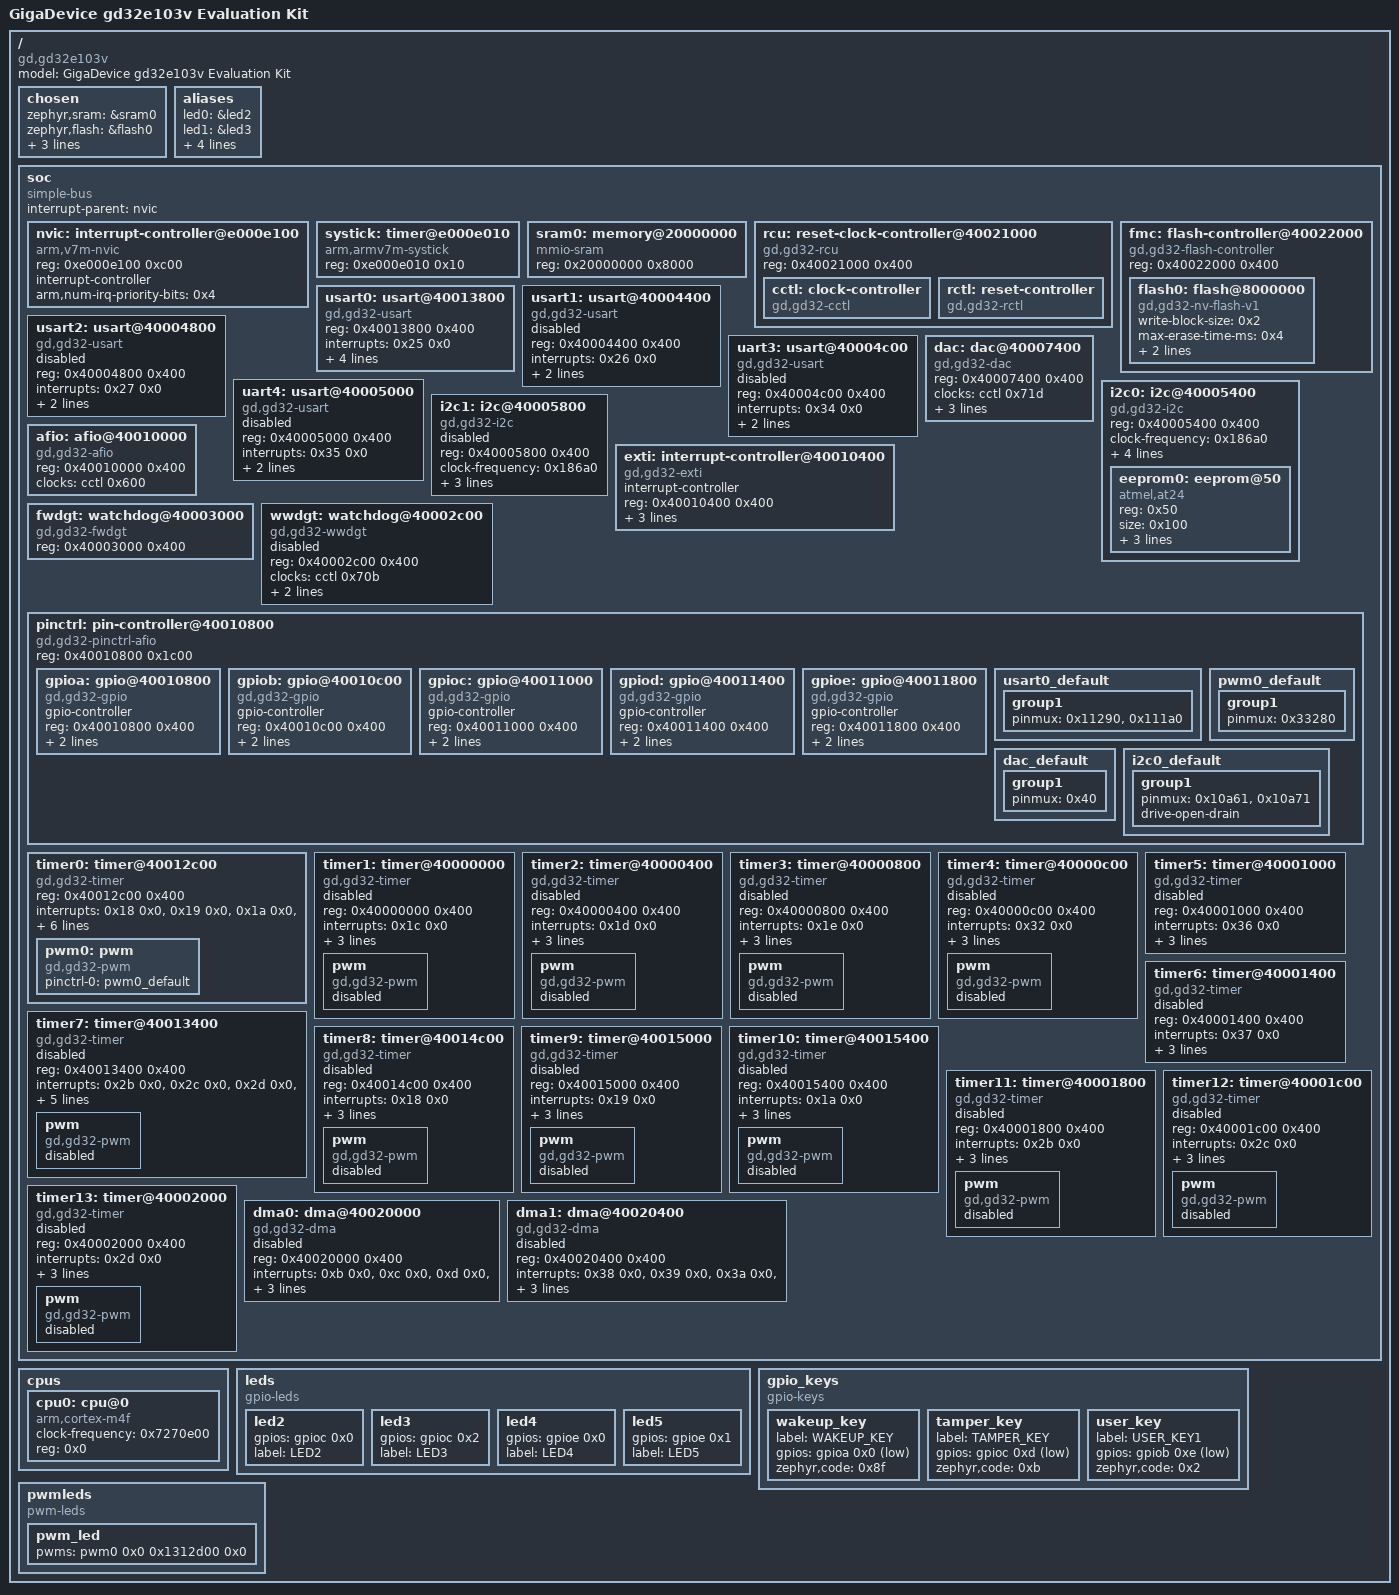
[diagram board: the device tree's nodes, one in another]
/dts-v1/;

/* node '/' defined in zephyr/dts/common/skeleton.dtsi:9 */
/ {
	#address-cells = < 0x1 >;                      /* in zephyr/dts/common/skeleton.dtsi:10 */
	#size-cells = < 0x1 >;                         /* in zephyr/dts/common/skeleton.dtsi:11 */
	model = "GigaDevice gd32e103v Evaluation Kit"; /* in zephyr/boards/gd/gd32e103v_eval/gd32e103v_eval.dts:13 */
	compatible = "gd,gd32e103v";                   /* in zephyr/boards/gd/gd32e103v_eval/gd32e103v_eval.dts:14 */

	/* node '/chosen' defined in zephyr/dts/common/skeleton.dtsi:13 */
	chosen {
		zephyr,sram = &sram0;           /* in zephyr/boards/gd/gd32e103v_eval/gd32e103v_eval.dts:17 */
		zephyr,flash = &flash0;         /* in zephyr/boards/gd/gd32e103v_eval/gd32e103v_eval.dts:18 */
		zephyr,console = &usart0;       /* in zephyr/boards/gd/gd32e103v_eval/gd32e103v_eval.dts:19 */
		zephyr,shell-uart = &usart0;    /* in zephyr/boards/gd/gd32e103v_eval/gd32e103v_eval.dts:20 */
		zephyr,flash-controller = &fmc; /* in zephyr/boards/gd/gd32e103v_eval/gd32e103v_eval.dts:21 */
	};

	/* node '/aliases' defined in zephyr/dts/common/skeleton.dtsi:15 */
	aliases {
		led0 = &led2;        /* in zephyr/boards/gd/gd32e103v_eval/gd32e103v_eval.dts:80 */
		led1 = &led3;        /* in zephyr/boards/gd/gd32e103v_eval/gd32e103v_eval.dts:81 */
		sw0 = &user_key;     /* in zephyr/boards/gd/gd32e103v_eval/gd32e103v_eval.dts:82 */
		pwm-led0 = &pwm_led; /* in zephyr/boards/gd/gd32e103v_eval/gd32e103v_eval.dts:83 */
		eeprom-0 = &eeprom0; /* in zephyr/boards/gd/gd32e103v_eval/gd32e103v_eval.dts:84 */
		watchdog0 = &fwdgt;  /* in zephyr/boards/gd/gd32e103v_eval/gd32e103v_eval.dts:85 */
	};

	/* node '/soc' defined in zephyr/dts/arm/armv7-m.dtsi:6 */
	soc {
		#address-cells = < 0x1 >;     /* in zephyr/dts/arm/armv7-m.dtsi:7 */
		#size-cells = < 0x1 >;        /* in zephyr/dts/arm/armv7-m.dtsi:8 */
		compatible = "simple-bus";    /* in zephyr/dts/arm/armv7-m.dtsi:9 */
		interrupt-parent = < &nvic >; /* in zephyr/dts/arm/armv7-m.dtsi:10 */
		ranges;                       /* in zephyr/dts/arm/armv7-m.dtsi:11 */

		/* node '/soc/interrupt-controller@e000e100' defined in zephyr/dts/arm/armv7-m.dtsi:13 */
		nvic: interrupt-controller@e000e100 {
			#address-cells = < 0x1 >;            /* in zephyr/dts/arm/armv7-m.dtsi:14 */
			compatible = "arm,v7m-nvic";         /* in zephyr/dts/arm/armv7-m.dtsi:15 */
			reg = < 0xe000e100 0xc00 >;          /* in zephyr/dts/arm/armv7-m.dtsi:16 */
			interrupt-controller;                /* in zephyr/dts/arm/armv7-m.dtsi:17 */
			#interrupt-cells = < 0x2 >;          /* in zephyr/dts/arm/armv7-m.dtsi:18 */
			arm,num-irq-priority-bits = < 0x4 >; /* in zephyr/dts/arm/gd/gd32e10x/gd32e10x.dtsi:493 */
			phandle = < 0x1 >;                   /* in zephyr/dts/arm/armv7-m.dtsi:10 */
		};

		/* node '/soc/timer@e000e010' defined in zephyr/dts/arm/armv7-m.dtsi:21 */
		systick: timer@e000e010 {
			compatible = "arm,armv7m-systick"; /* in zephyr/dts/arm/armv7-m.dtsi:22 */
			reg = < 0xe000e010 0x10 >;         /* in zephyr/dts/arm/armv7-m.dtsi:23 */
		};

		/* node '/soc/memory@20000000' defined in zephyr/dts/arm/gd/gd32e10x/gd32e10x.dtsi:30 */
		sram0: memory@20000000 {
			compatible = "mmio-sram";    /* in zephyr/dts/arm/gd/gd32e10x/gd32e10x.dtsi:31 */
			reg = < 0x20000000 0x8000 >; /* in zephyr/dts/arm/gd/gd32e10x/gd32e103vbt6.dtsi:15 */
		};

		/* node '/soc/reset-clock-controller@40021000' defined in zephyr/dts/arm/gd/gd32e10x/gd32e10x.dtsi:34 */
		rcu: reset-clock-controller@40021000 {
			compatible = "gd,gd32-rcu"; /* in zephyr/dts/arm/gd/gd32e10x/gd32e10x.dtsi:35 */
			reg = < 0x40021000 0x400 >; /* in zephyr/dts/arm/gd/gd32e10x/gd32e10x.dtsi:36 */
			status = "okay";            /* in zephyr/dts/arm/gd/gd32e10x/gd32e10x.dtsi:37 */

			/* node '/soc/reset-clock-controller@40021000/clock-controller' defined in zephyr/dts/arm/gd/gd32e10x/gd32e10x.dtsi:39 */
			cctl: clock-controller {
				compatible = "gd,gd32-cctl"; /* in zephyr/dts/arm/gd/gd32e10x/gd32e10x.dtsi:40 */
				#clock-cells = < 0x1 >;      /* in zephyr/dts/arm/gd/gd32e10x/gd32e10x.dtsi:41 */
				status = "okay";             /* in zephyr/dts/arm/gd/gd32e10x/gd32e10x.dtsi:42 */
				phandle = < 0x2 >;           /* in zephyr/dts/arm/gd/gd32e10x/gd32e10x.dtsi:70 */
			};

			/* node '/soc/reset-clock-controller@40021000/reset-controller' defined in zephyr/dts/arm/gd/gd32e10x/gd32e10x.dtsi:45 */
			rctl: reset-controller {
				compatible = "gd,gd32-rctl"; /* in zephyr/dts/arm/gd/gd32e10x/gd32e10x.dtsi:46 */
				#reset-cells = < 0x1 >;      /* in zephyr/dts/arm/gd/gd32e10x/gd32e10x.dtsi:47 */
				status = "okay";             /* in zephyr/dts/arm/gd/gd32e10x/gd32e10x.dtsi:48 */
				phandle = < 0x3 >;           /* in zephyr/dts/arm/gd/gd32e10x/gd32e10x.dtsi:71 */
			};
		};

		/* node '/soc/flash-controller@40022000' defined in zephyr/dts/arm/gd/gd32e10x/gd32e10x.dtsi:52 */
		fmc: flash-controller@40022000 {
			compatible = "gd,gd32-flash-controller"; /* in zephyr/dts/arm/gd/gd32e10x/gd32e10x.dtsi:53 */
			reg = < 0x40022000 0x400 >;              /* in zephyr/dts/arm/gd/gd32e10x/gd32e10x.dtsi:54 */
			#address-cells = < 0x1 >;                /* in zephyr/dts/arm/gd/gd32e10x/gd32e10x.dtsi:55 */
			#size-cells = < 0x1 >;                   /* in zephyr/dts/arm/gd/gd32e10x/gd32e10x.dtsi:56 */

			/* node '/soc/flash-controller@40022000/flash@8000000' defined in zephyr/dts/arm/gd/gd32e10x/gd32e10x.dtsi:58 */
			flash0: flash@8000000 {
				compatible = "gd,gd32-nv-flash-v1",
				             "soc-nv-flash";        /* in zephyr/dts/arm/gd/gd32e10x/gd32e10x.dtsi:59 */
				write-block-size = < 0x2 >;         /* in zephyr/dts/arm/gd/gd32e10x/gd32e10x.dtsi:60 */
				max-erase-time-ms = < 0x4 >;        /* in zephyr/dts/arm/gd/gd32e10x/gd32e10x.dtsi:61 */
				page-size = < 0x400 >;              /* in zephyr/dts/arm/gd/gd32e10x/gd32e10x.dtsi:62 */
				reg = < 0x8000000 0x20000 >;        /* in zephyr/dts/arm/gd/gd32e10x/gd32e103vbt6.dtsi:11 */
			};
		};

		/* node '/soc/usart@40013800' defined in zephyr/dts/arm/gd/gd32e10x/gd32e10x.dtsi:66 */
		usart0: usart@40013800 {
			compatible = "gd,gd32-usart";    /* in zephyr/dts/arm/gd/gd32e10x/gd32e10x.dtsi:67 */
			reg = < 0x40013800 0x400 >;      /* in zephyr/dts/arm/gd/gd32e10x/gd32e10x.dtsi:68 */
			interrupts = < 0x25 0x0 >;       /* in zephyr/dts/arm/gd/gd32e10x/gd32e10x.dtsi:69 */
			clocks = < &cctl 0x60e >;        /* in zephyr/dts/arm/gd/gd32e10x/gd32e10x.dtsi:70 */
			resets = < &rctl 0x30e >;        /* in zephyr/dts/arm/gd/gd32e10x/gd32e10x.dtsi:71 */
			status = "okay";                 /* in zephyr/boards/gd/gd32e103v_eval/gd32e103v_eval.dts:110 */
			current-speed = < 0x1c200 >;     /* in zephyr/boards/gd/gd32e103v_eval/gd32e103v_eval.dts:111 */
			pinctrl-0 = < &usart0_default >; /* in zephyr/boards/gd/gd32e103v_eval/gd32e103v_eval.dts:112 */
			pinctrl-names = "default";       /* in zephyr/boards/gd/gd32e103v_eval/gd32e103v_eval.dts:113 */
		};

		/* node '/soc/usart@40004400' defined in zephyr/dts/arm/gd/gd32e10x/gd32e10x.dtsi:75 */
		usart1: usart@40004400 {
			compatible = "gd,gd32-usart"; /* in zephyr/dts/arm/gd/gd32e10x/gd32e10x.dtsi:76 */
			reg = < 0x40004400 0x400 >;   /* in zephyr/dts/arm/gd/gd32e10x/gd32e10x.dtsi:77 */
			interrupts = < 0x26 0x0 >;    /* in zephyr/dts/arm/gd/gd32e10x/gd32e10x.dtsi:78 */
			clocks = < &cctl 0x711 >;     /* in zephyr/dts/arm/gd/gd32e10x/gd32e10x.dtsi:79 */
			resets = < &rctl 0x411 >;     /* in zephyr/dts/arm/gd/gd32e10x/gd32e10x.dtsi:80 */
			status = "disabled";          /* in zephyr/dts/arm/gd/gd32e10x/gd32e10x.dtsi:81 */
		};

		/* node '/soc/usart@40004800' defined in zephyr/dts/arm/gd/gd32e10x/gd32e10x.dtsi:84 */
		usart2: usart@40004800 {
			compatible = "gd,gd32-usart"; /* in zephyr/dts/arm/gd/gd32e10x/gd32e10x.dtsi:85 */
			reg = < 0x40004800 0x400 >;   /* in zephyr/dts/arm/gd/gd32e10x/gd32e10x.dtsi:86 */
			interrupts = < 0x27 0x0 >;    /* in zephyr/dts/arm/gd/gd32e10x/gd32e10x.dtsi:87 */
			clocks = < &cctl 0x712 >;     /* in zephyr/dts/arm/gd/gd32e10x/gd32e10x.dtsi:88 */
			resets = < &rctl 0x412 >;     /* in zephyr/dts/arm/gd/gd32e10x/gd32e10x.dtsi:89 */
			status = "disabled";          /* in zephyr/dts/arm/gd/gd32e10x/gd32e10x.dtsi:90 */
		};

		/* node '/soc/usart@40004c00' defined in zephyr/dts/arm/gd/gd32e10x/gd32e10x.dtsi:93 */
		uart3: usart@40004c00 {
			compatible = "gd,gd32-usart"; /* in zephyr/dts/arm/gd/gd32e10x/gd32e10x.dtsi:94 */
			reg = < 0x40004c00 0x400 >;   /* in zephyr/dts/arm/gd/gd32e10x/gd32e10x.dtsi:95 */
			interrupts = < 0x34 0x0 >;    /* in zephyr/dts/arm/gd/gd32e10x/gd32e10x.dtsi:96 */
			clocks = < &cctl 0x713 >;     /* in zephyr/dts/arm/gd/gd32e10x/gd32e10x.dtsi:97 */
			resets = < &rctl 0x413 >;     /* in zephyr/dts/arm/gd/gd32e10x/gd32e10x.dtsi:98 */
			status = "disabled";          /* in zephyr/dts/arm/gd/gd32e10x/gd32e10x.dtsi:99 */
		};

		/* node '/soc/usart@40005000' defined in zephyr/dts/arm/gd/gd32e10x/gd32e10x.dtsi:102 */
		uart4: usart@40005000 {
			compatible = "gd,gd32-usart"; /* in zephyr/dts/arm/gd/gd32e10x/gd32e10x.dtsi:103 */
			reg = < 0x40005000 0x400 >;   /* in zephyr/dts/arm/gd/gd32e10x/gd32e10x.dtsi:104 */
			interrupts = < 0x35 0x0 >;    /* in zephyr/dts/arm/gd/gd32e10x/gd32e10x.dtsi:105 */
			clocks = < &cctl 0x714 >;     /* in zephyr/dts/arm/gd/gd32e10x/gd32e10x.dtsi:106 */
			resets = < &rctl 0x414 >;     /* in zephyr/dts/arm/gd/gd32e10x/gd32e10x.dtsi:107 */
			status = "disabled";          /* in zephyr/dts/arm/gd/gd32e10x/gd32e10x.dtsi:108 */
		};

		/* node '/soc/dac@40007400' defined in zephyr/dts/arm/gd/gd32e10x/gd32e10x.dtsi:111 */
		dac: dac@40007400 {
			compatible = "gd,gd32-dac";   /* in zephyr/dts/arm/gd/gd32e10x/gd32e10x.dtsi:112 */
			reg = < 0x40007400 0x400 >;   /* in zephyr/dts/arm/gd/gd32e10x/gd32e10x.dtsi:113 */
			clocks = < &cctl 0x71d >;     /* in zephyr/dts/arm/gd/gd32e10x/gd32e10x.dtsi:114 */
			resets = < &rctl 0x41d >;     /* in zephyr/dts/arm/gd/gd32e10x/gd32e10x.dtsi:115 */
			num-channels = < 0x2 >;       /* in zephyr/dts/arm/gd/gd32e10x/gd32e10x.dtsi:116 */
			#io-channel-cells = < 0x1 >;  /* in zephyr/dts/arm/gd/gd32e10x/gd32e10x.dtsi:118 */
			status = "okay";              /* in zephyr/boards/gd/gd32e103v_eval/gd32e103v_eval.dts:144 */
			pinctrl-0 = < &dac_default >; /* in zephyr/boards/gd/gd32e103v_eval/gd32e103v_eval.dts:145 */
			pinctrl-names = "default";    /* in zephyr/boards/gd/gd32e103v_eval/gd32e103v_eval.dts:146 */
		};

		/* node '/soc/i2c@40005400' defined in zephyr/dts/arm/gd/gd32e10x/gd32e10x.dtsi:121 */
		i2c0: i2c@40005400 {
			compatible = "gd,gd32-i2c";    /* in zephyr/dts/arm/gd/gd32e10x/gd32e10x.dtsi:122 */
			reg = < 0x40005400 0x400 >;    /* in zephyr/dts/arm/gd/gd32e10x/gd32e10x.dtsi:123 */
			#address-cells = < 0x1 >;      /* in zephyr/dts/arm/gd/gd32e10x/gd32e10x.dtsi:124 */
			#size-cells = < 0x0 >;         /* in zephyr/dts/arm/gd/gd32e10x/gd32e10x.dtsi:125 */
			clock-frequency = < 0x186a0 >; /* in zephyr/dts/arm/gd/gd32e10x/gd32e10x.dtsi:126 */
			interrupts = < 0x1f 0x0 >,
			             < 0x20 0x0 >;     /* in zephyr/dts/arm/gd/gd32e10x/gd32e10x.dtsi:127 */
			interrupt-names = "event",
			                  "error";     /* in zephyr/dts/arm/gd/gd32e10x/gd32e10x.dtsi:128 */
			clocks = < &cctl 0x715 >;      /* in zephyr/dts/arm/gd/gd32e10x/gd32e10x.dtsi:129 */
			resets = < &rctl 0x415 >;      /* in zephyr/dts/arm/gd/gd32e10x/gd32e10x.dtsi:130 */
			status = "okay";               /* in zephyr/boards/gd/gd32e103v_eval/gd32e103v_eval.dts:128 */
			pinctrl-0 = < &i2c0_default >; /* in zephyr/boards/gd/gd32e103v_eval/gd32e103v_eval.dts:129 */
			pinctrl-names = "default";     /* in zephyr/boards/gd/gd32e103v_eval/gd32e103v_eval.dts:130 */

			/* node '/soc/i2c@40005400/eeprom@50' defined in zephyr/boards/gd/gd32e103v_eval/gd32e103v_eval.dts:132 */
			eeprom0: eeprom@50 {
				compatible = "atmel,at24"; /* in zephyr/boards/gd/gd32e103v_eval/gd32e103v_eval.dts:133 */
				reg = < 0x50 >;            /* in zephyr/boards/gd/gd32e103v_eval/gd32e103v_eval.dts:134 */
				status = "okay";           /* in zephyr/boards/gd/gd32e103v_eval/gd32e103v_eval.dts:135 */
				size = < 0x100 >;          /* in zephyr/boards/gd/gd32e103v_eval/gd32e103v_eval.dts:136 */
				pagesize = < 0x8 >;        /* in zephyr/boards/gd/gd32e103v_eval/gd32e103v_eval.dts:137 */
				address-width = < 0x8 >;   /* in zephyr/boards/gd/gd32e103v_eval/gd32e103v_eval.dts:138 */
				timeout = < 0x5 >;         /* in zephyr/boards/gd/gd32e103v_eval/gd32e103v_eval.dts:139 */
			};
		};

		/* node '/soc/i2c@40005800' defined in zephyr/dts/arm/gd/gd32e10x/gd32e10x.dtsi:134 */
		i2c1: i2c@40005800 {
			compatible = "gd,gd32-i2c";    /* in zephyr/dts/arm/gd/gd32e10x/gd32e10x.dtsi:135 */
			reg = < 0x40005800 0x400 >;    /* in zephyr/dts/arm/gd/gd32e10x/gd32e10x.dtsi:136 */
			#address-cells = < 0x1 >;      /* in zephyr/dts/arm/gd/gd32e10x/gd32e10x.dtsi:137 */
			#size-cells = < 0x0 >;         /* in zephyr/dts/arm/gd/gd32e10x/gd32e10x.dtsi:138 */
			clock-frequency = < 0x186a0 >; /* in zephyr/dts/arm/gd/gd32e10x/gd32e10x.dtsi:139 */
			interrupts = < 0x21 0x0 >,
			             < 0x22 0x0 >;     /* in zephyr/dts/arm/gd/gd32e10x/gd32e10x.dtsi:140 */
			interrupt-names = "event",
			                  "error";     /* in zephyr/dts/arm/gd/gd32e10x/gd32e10x.dtsi:141 */
			clocks = < &cctl 0x716 >;      /* in zephyr/dts/arm/gd/gd32e10x/gd32e10x.dtsi:142 */
			resets = < &rctl 0x416 >;      /* in zephyr/dts/arm/gd/gd32e10x/gd32e10x.dtsi:143 */
			status = "disabled";           /* in zephyr/dts/arm/gd/gd32e10x/gd32e10x.dtsi:144 */
		};

		/* node '/soc/afio@40010000' defined in zephyr/dts/arm/gd/gd32e10x/gd32e10x.dtsi:147 */
		afio: afio@40010000 {
			compatible = "gd,gd32-afio"; /* in zephyr/dts/arm/gd/gd32e10x/gd32e10x.dtsi:148 */
			reg = < 0x40010000 0x400 >;  /* in zephyr/dts/arm/gd/gd32e10x/gd32e10x.dtsi:149 */
			clocks = < &cctl 0x600 >;    /* in zephyr/dts/arm/gd/gd32e10x/gd32e10x.dtsi:150 */
			status = "okay";             /* in zephyr/dts/arm/gd/gd32e10x/gd32e10x.dtsi:151 */
		};

		/* node '/soc/interrupt-controller@40010400' defined in zephyr/dts/arm/gd/gd32e10x/gd32e10x.dtsi:154 */
		exti: interrupt-controller@40010400 {
			compatible = "gd,gd32-exti";   /* in zephyr/dts/arm/gd/gd32e10x/gd32e10x.dtsi:155 */
			interrupt-controller;          /* in zephyr/dts/arm/gd/gd32e10x/gd32e10x.dtsi:156 */
			#interrupt-cells = < 0x1 >;    /* in zephyr/dts/arm/gd/gd32e10x/gd32e10x.dtsi:157 */
			reg = < 0x40010400 0x400 >;    /* in zephyr/dts/arm/gd/gd32e10x/gd32e10x.dtsi:158 */
			num-lines = < 0x13 >;          /* in zephyr/dts/arm/gd/gd32e10x/gd32e10x.dtsi:159 */
			interrupts = < 0x6 0x0 >,
			             < 0x7 0x0 >,
			             < 0x8 0x0 >,
			             < 0x9 0x0 >,
			             < 0xa 0x0 >,
			             < 0x17 0x0 >,
			             < 0x28 0x0 >;     /* in zephyr/dts/arm/gd/gd32e10x/gd32e10x.dtsi:160 */
			interrupt-names = "line0",
			                  "line1",
			                  "line2",
			                  "line3",
			                  "line4",
			                  "line5-9",
			                  "line10-15"; /* in zephyr/dts/arm/gd/gd32e10x/gd32e10x.dtsi:162 */
			status = "okay";               /* in zephyr/dts/arm/gd/gd32e10x/gd32e10x.dtsi:164 */
		};

		/* node '/soc/watchdog@40003000' defined in zephyr/dts/arm/gd/gd32e10x/gd32e10x.dtsi:167 */
		fwdgt: watchdog@40003000 {
			compatible = "gd,gd32-fwdgt"; /* in zephyr/dts/arm/gd/gd32e10x/gd32e10x.dtsi:168 */
			reg = < 0x40003000 0x400 >;   /* in zephyr/dts/arm/gd/gd32e10x/gd32e10x.dtsi:169 */
			status = "okay";              /* in zephyr/boards/gd/gd32e103v_eval/gd32e103v_eval.dts:150 */
		};

		/* node '/soc/watchdog@40002c00' defined in zephyr/dts/arm/gd/gd32e10x/gd32e10x.dtsi:173 */
		wwdgt: watchdog@40002c00 {
			compatible = "gd,gd32-wwdgt"; /* in zephyr/dts/arm/gd/gd32e10x/gd32e10x.dtsi:174 */
			reg = < 0x40002c00 0x400 >;   /* in zephyr/dts/arm/gd/gd32e10x/gd32e10x.dtsi:175 */
			clocks = < &cctl 0x70b >;     /* in zephyr/dts/arm/gd/gd32e10x/gd32e10x.dtsi:176 */
			resets = < &rctl 0x40b >;     /* in zephyr/dts/arm/gd/gd32e10x/gd32e10x.dtsi:177 */
			interrupts = < 0x0 0x0 >;     /* in zephyr/dts/arm/gd/gd32e10x/gd32e10x.dtsi:178 */
			status = "disabled";          /* in zephyr/dts/arm/gd/gd32e10x/gd32e10x.dtsi:179 */
		};

		/* node '/soc/pin-controller@40010800' defined in zephyr/dts/arm/gd/gd32e10x/gd32e10x.dtsi:182 */
		pinctrl: pin-controller@40010800 {
			compatible = "gd,gd32-pinctrl-afio"; /* in zephyr/dts/arm/gd/gd32e10x/gd32e10x.dtsi:183 */
			reg = < 0x40010800 0x1c00 >;         /* in zephyr/dts/arm/gd/gd32e10x/gd32e10x.dtsi:184 */
			#address-cells = < 0x1 >;            /* in zephyr/dts/arm/gd/gd32e10x/gd32e10x.dtsi:185 */
			#size-cells = < 0x1 >;               /* in zephyr/dts/arm/gd/gd32e10x/gd32e10x.dtsi:186 */
			status = "okay";                     /* in zephyr/dts/arm/gd/gd32e10x/gd32e10x.dtsi:187 */

			/* node '/soc/pin-controller@40010800/gpio@40010800' defined in zephyr/dts/arm/gd/gd32e10x/gd32e10x.dtsi:189 */
			gpioa: gpio@40010800 {
				compatible = "gd,gd32-gpio"; /* in zephyr/dts/arm/gd/gd32e10x/gd32e10x.dtsi:190 */
				gpio-controller;             /* in zephyr/dts/arm/gd/gd32e10x/gd32e10x.dtsi:191 */
				#gpio-cells = < 0x2 >;       /* in zephyr/dts/arm/gd/gd32e10x/gd32e10x.dtsi:192 */
				reg = < 0x40010800 0x400 >;  /* in zephyr/dts/arm/gd/gd32e10x/gd32e10x.dtsi:193 */
				clocks = < &cctl 0x602 >;    /* in zephyr/dts/arm/gd/gd32e10x/gd32e10x.dtsi:194 */
				resets = < &rctl 0x302 >;    /* in zephyr/dts/arm/gd/gd32e10x/gd32e10x.dtsi:195 */
				status = "okay";             /* in zephyr/boards/gd/gd32e103v_eval/gd32e103v_eval.dts:90 */
				phandle = < 0xa >;           /* in zephyr/boards/gd/gd32e103v_eval/gd32e103v_eval.dts:53 */
			};

			/* node '/soc/pin-controller@40010800/gpio@40010c00' defined in zephyr/dts/arm/gd/gd32e10x/gd32e10x.dtsi:199 */
			gpiob: gpio@40010c00 {
				compatible = "gd,gd32-gpio"; /* in zephyr/dts/arm/gd/gd32e10x/gd32e10x.dtsi:200 */
				gpio-controller;             /* in zephyr/dts/arm/gd/gd32e10x/gd32e10x.dtsi:201 */
				#gpio-cells = < 0x2 >;       /* in zephyr/dts/arm/gd/gd32e10x/gd32e10x.dtsi:202 */
				reg = < 0x40010c00 0x400 >;  /* in zephyr/dts/arm/gd/gd32e10x/gd32e10x.dtsi:203 */
				clocks = < &cctl 0x603 >;    /* in zephyr/dts/arm/gd/gd32e10x/gd32e10x.dtsi:204 */
				resets = < &rctl 0x303 >;    /* in zephyr/dts/arm/gd/gd32e10x/gd32e10x.dtsi:205 */
				status = "okay";             /* in zephyr/boards/gd/gd32e103v_eval/gd32e103v_eval.dts:94 */
				phandle = < 0xb >;           /* in zephyr/boards/gd/gd32e103v_eval/gd32e103v_eval.dts:65 */
			};

			/* node '/soc/pin-controller@40010800/gpio@40011000' defined in zephyr/dts/arm/gd/gd32e10x/gd32e10x.dtsi:209 */
			gpioc: gpio@40011000 {
				compatible = "gd,gd32-gpio"; /* in zephyr/dts/arm/gd/gd32e10x/gd32e10x.dtsi:210 */
				gpio-controller;             /* in zephyr/dts/arm/gd/gd32e10x/gd32e10x.dtsi:211 */
				#gpio-cells = < 0x2 >;       /* in zephyr/dts/arm/gd/gd32e10x/gd32e10x.dtsi:212 */
				reg = < 0x40011000 0x400 >;  /* in zephyr/dts/arm/gd/gd32e10x/gd32e10x.dtsi:213 */
				clocks = < &cctl 0x604 >;    /* in zephyr/dts/arm/gd/gd32e10x/gd32e10x.dtsi:214 */
				resets = < &rctl 0x304 >;    /* in zephyr/dts/arm/gd/gd32e10x/gd32e10x.dtsi:215 */
				status = "okay";             /* in zephyr/boards/gd/gd32e103v_eval/gd32e103v_eval.dts:98 */
				phandle = < 0x8 >;           /* in zephyr/boards/gd/gd32e103v_eval/gd32e103v_eval.dts:28 */
			};

			/* node '/soc/pin-controller@40010800/gpio@40011400' defined in zephyr/dts/arm/gd/gd32e10x/gd32e10x.dtsi:219 */
			gpiod: gpio@40011400 {
				compatible = "gd,gd32-gpio"; /* in zephyr/dts/arm/gd/gd32e10x/gd32e10x.dtsi:220 */
				gpio-controller;             /* in zephyr/dts/arm/gd/gd32e10x/gd32e10x.dtsi:221 */
				#gpio-cells = < 0x2 >;       /* in zephyr/dts/arm/gd/gd32e10x/gd32e10x.dtsi:222 */
				reg = < 0x40011400 0x400 >;  /* in zephyr/dts/arm/gd/gd32e10x/gd32e10x.dtsi:223 */
				clocks = < &cctl 0x605 >;    /* in zephyr/dts/arm/gd/gd32e10x/gd32e10x.dtsi:224 */
				resets = < &rctl 0x305 >;    /* in zephyr/dts/arm/gd/gd32e10x/gd32e10x.dtsi:225 */
				status = "okay";             /* in zephyr/boards/gd/gd32e103v_eval/gd32e103v_eval.dts:102 */
			};

			/* node '/soc/pin-controller@40010800/gpio@40011800' defined in zephyr/dts/arm/gd/gd32e10x/gd32e10x.dtsi:229 */
			gpioe: gpio@40011800 {
				compatible = "gd,gd32-gpio"; /* in zephyr/dts/arm/gd/gd32e10x/gd32e10x.dtsi:230 */
				gpio-controller;             /* in zephyr/dts/arm/gd/gd32e10x/gd32e10x.dtsi:231 */
				#gpio-cells = < 0x2 >;       /* in zephyr/dts/arm/gd/gd32e10x/gd32e10x.dtsi:232 */
				reg = < 0x40011800 0x400 >;  /* in zephyr/dts/arm/gd/gd32e10x/gd32e10x.dtsi:233 */
				clocks = < &cctl 0x606 >;    /* in zephyr/dts/arm/gd/gd32e10x/gd32e10x.dtsi:234 */
				resets = < &rctl 0x306 >;    /* in zephyr/dts/arm/gd/gd32e10x/gd32e10x.dtsi:235 */
				status = "okay";             /* in zephyr/boards/gd/gd32e103v_eval/gd32e103v_eval.dts:106 */
				phandle = < 0x9 >;           /* in zephyr/boards/gd/gd32e103v_eval/gd32e103v_eval.dts:38 */
			};

			/* node '/soc/pin-controller@40010800/usart0_default' defined in zephyr/boards/gd/gd32e103v_eval/gd32e103v_eval-pinctrl.dtsi:9 */
			usart0_default: usart0_default {
				phandle = < 0x4 >; /* in zephyr/boards/gd/gd32e103v_eval/gd32e103v_eval.dts:112 */

				/* node '/soc/pin-controller@40010800/usart0_default/group1' defined in zephyr/boards/gd/gd32e103v_eval/gd32e103v_eval-pinctrl.dtsi:10 */
				group1 {
					pinmux = < 0x11290 >,
					         < 0x111a0 >; /* in zephyr/boards/gd/gd32e103v_eval/gd32e103v_eval-pinctrl.dtsi:11 */
				};
			};

			/* node '/soc/pin-controller@40010800/pwm0_default' defined in zephyr/boards/gd/gd32e103v_eval/gd32e103v_eval-pinctrl.dtsi:15 */
			pwm0_default: pwm0_default {
				phandle = < 0x7 >; /* in zephyr/boards/gd/gd32e103v_eval/gd32e103v_eval.dts:122 */

				/* node '/soc/pin-controller@40010800/pwm0_default/group1' defined in zephyr/boards/gd/gd32e103v_eval/gd32e103v_eval-pinctrl.dtsi:16 */
				group1 {
					pinmux = < 0x33280 >; /* in zephyr/boards/gd/gd32e103v_eval/gd32e103v_eval-pinctrl.dtsi:17 */
				};
			};

			/* node '/soc/pin-controller@40010800/dac_default' defined in zephyr/boards/gd/gd32e103v_eval/gd32e103v_eval-pinctrl.dtsi:21 */
			dac_default: dac_default {
				phandle = < 0x5 >; /* in zephyr/boards/gd/gd32e103v_eval/gd32e103v_eval.dts:145 */

				/* node '/soc/pin-controller@40010800/dac_default/group1' defined in zephyr/boards/gd/gd32e103v_eval/gd32e103v_eval-pinctrl.dtsi:22 */
				group1 {
					pinmux = < 0x40 >; /* in zephyr/boards/gd/gd32e103v_eval/gd32e103v_eval-pinctrl.dtsi:23 */
				};
			};

			/* node '/soc/pin-controller@40010800/i2c0_default' defined in zephyr/boards/gd/gd32e103v_eval/gd32e103v_eval-pinctrl.dtsi:27 */
			i2c0_default: i2c0_default {
				phandle = < 0x6 >; /* in zephyr/boards/gd/gd32e103v_eval/gd32e103v_eval.dts:129 */

				/* node '/soc/pin-controller@40010800/i2c0_default/group1' defined in zephyr/boards/gd/gd32e103v_eval/gd32e103v_eval-pinctrl.dtsi:28 */
				group1 {
					pinmux = < 0x10a61 >,
					         < 0x10a71 >; /* in zephyr/boards/gd/gd32e103v_eval/gd32e103v_eval-pinctrl.dtsi:29 */
					drive-open-drain;     /* in zephyr/boards/gd/gd32e103v_eval/gd32e103v_eval-pinctrl.dtsi:30 */
				};
			};
		};

		/* node '/soc/timer@40012c00' defined in zephyr/dts/arm/gd/gd32e10x/gd32e10x.dtsi:240 */
		timer0: timer@40012c00 {
			compatible = "gd,gd32-timer"; /* in zephyr/dts/arm/gd/gd32e10x/gd32e10x.dtsi:241 */
			reg = < 0x40012c00 0x400 >;   /* in zephyr/dts/arm/gd/gd32e10x/gd32e10x.dtsi:242 */
			interrupts = < 0x18 0x0 >,
			             < 0x19 0x0 >,
			             < 0x1a 0x0 >,
			             < 0x1b 0x0 >;    /* in zephyr/dts/arm/gd/gd32e10x/gd32e10x.dtsi:243 */
			interrupt-names = "brk",
			                  "up",
			                  "trgcom",
			                  "cc";       /* in zephyr/dts/arm/gd/gd32e10x/gd32e10x.dtsi:244 */
			clocks = < &cctl 0x60b >;     /* in zephyr/dts/arm/gd/gd32e10x/gd32e10x.dtsi:245 */
			resets = < &rctl 0x30b >;     /* in zephyr/dts/arm/gd/gd32e10x/gd32e10x.dtsi:246 */
			is-advanced;                  /* in zephyr/dts/arm/gd/gd32e10x/gd32e10x.dtsi:247 */
			channels = < 0x4 >;           /* in zephyr/dts/arm/gd/gd32e10x/gd32e10x.dtsi:248 */
			status = "okay";              /* in zephyr/boards/gd/gd32e103v_eval/gd32e103v_eval.dts:117 */
			prescaler = < 0x80 >;         /* in zephyr/boards/gd/gd32e103v_eval/gd32e103v_eval.dts:118 */

			/* node '/soc/timer@40012c00/pwm' defined in zephyr/dts/arm/gd/gd32e10x/gd32e10x.dtsi:251 */
			pwm0: pwm {
				compatible = "gd,gd32-pwm";    /* in zephyr/dts/arm/gd/gd32e10x/gd32e10x.dtsi:252 */
				#pwm-cells = < 0x3 >;          /* in zephyr/dts/arm/gd/gd32e10x/gd32e10x.dtsi:254 */
				status = "okay";               /* in zephyr/boards/gd/gd32e103v_eval/gd32e103v_eval.dts:121 */
				pinctrl-0 = < &pwm0_default >; /* in zephyr/boards/gd/gd32e103v_eval/gd32e103v_eval.dts:122 */
				pinctrl-names = "default";     /* in zephyr/boards/gd/gd32e103v_eval/gd32e103v_eval.dts:123 */
				phandle = < 0xc >;             /* in zephyr/boards/gd/gd32e103v_eval/gd32e103v_eval.dts:75 */
			};
		};

		/* node '/soc/timer@40000000' defined in zephyr/dts/arm/gd/gd32e10x/gd32e10x.dtsi:258 */
		timer1: timer@40000000 {
			compatible = "gd,gd32-timer"; /* in zephyr/dts/arm/gd/gd32e10x/gd32e10x.dtsi:259 */
			reg = < 0x40000000 0x400 >;   /* in zephyr/dts/arm/gd/gd32e10x/gd32e10x.dtsi:260 */
			interrupts = < 0x1c 0x0 >;    /* in zephyr/dts/arm/gd/gd32e10x/gd32e10x.dtsi:261 */
			interrupt-names = "global";   /* in zephyr/dts/arm/gd/gd32e10x/gd32e10x.dtsi:262 */
			clocks = < &cctl 0x700 >;     /* in zephyr/dts/arm/gd/gd32e10x/gd32e10x.dtsi:263 */
			resets = < &rctl 0x400 >;     /* in zephyr/dts/arm/gd/gd32e10x/gd32e10x.dtsi:264 */
			channels = < 0x4 >;           /* in zephyr/dts/arm/gd/gd32e10x/gd32e10x.dtsi:265 */
			status = "disabled";          /* in zephyr/dts/arm/gd/gd32e10x/gd32e10x.dtsi:266 */

			/* node '/soc/timer@40000000/pwm' defined in zephyr/dts/arm/gd/gd32e10x/gd32e10x.dtsi:268 */
			pwm {
				compatible = "gd,gd32-pwm"; /* in zephyr/dts/arm/gd/gd32e10x/gd32e10x.dtsi:269 */
				status = "disabled";        /* in zephyr/dts/arm/gd/gd32e10x/gd32e10x.dtsi:270 */
				#pwm-cells = < 0x3 >;       /* in zephyr/dts/arm/gd/gd32e10x/gd32e10x.dtsi:271 */
			};
		};

		/* node '/soc/timer@40000400' defined in zephyr/dts/arm/gd/gd32e10x/gd32e10x.dtsi:275 */
		timer2: timer@40000400 {
			compatible = "gd,gd32-timer"; /* in zephyr/dts/arm/gd/gd32e10x/gd32e10x.dtsi:276 */
			reg = < 0x40000400 0x400 >;   /* in zephyr/dts/arm/gd/gd32e10x/gd32e10x.dtsi:277 */
			interrupts = < 0x1d 0x0 >;    /* in zephyr/dts/arm/gd/gd32e10x/gd32e10x.dtsi:278 */
			interrupt-names = "global";   /* in zephyr/dts/arm/gd/gd32e10x/gd32e10x.dtsi:279 */
			clocks = < &cctl 0x701 >;     /* in zephyr/dts/arm/gd/gd32e10x/gd32e10x.dtsi:280 */
			resets = < &rctl 0x401 >;     /* in zephyr/dts/arm/gd/gd32e10x/gd32e10x.dtsi:281 */
			channels = < 0x4 >;           /* in zephyr/dts/arm/gd/gd32e10x/gd32e10x.dtsi:282 */
			status = "disabled";          /* in zephyr/dts/arm/gd/gd32e10x/gd32e10x.dtsi:283 */

			/* node '/soc/timer@40000400/pwm' defined in zephyr/dts/arm/gd/gd32e10x/gd32e10x.dtsi:285 */
			pwm {
				compatible = "gd,gd32-pwm"; /* in zephyr/dts/arm/gd/gd32e10x/gd32e10x.dtsi:286 */
				status = "disabled";        /* in zephyr/dts/arm/gd/gd32e10x/gd32e10x.dtsi:287 */
				#pwm-cells = < 0x3 >;       /* in zephyr/dts/arm/gd/gd32e10x/gd32e10x.dtsi:288 */
			};
		};

		/* node '/soc/timer@40000800' defined in zephyr/dts/arm/gd/gd32e10x/gd32e10x.dtsi:292 */
		timer3: timer@40000800 {
			compatible = "gd,gd32-timer"; /* in zephyr/dts/arm/gd/gd32e10x/gd32e10x.dtsi:293 */
			reg = < 0x40000800 0x400 >;   /* in zephyr/dts/arm/gd/gd32e10x/gd32e10x.dtsi:294 */
			interrupts = < 0x1e 0x0 >;    /* in zephyr/dts/arm/gd/gd32e10x/gd32e10x.dtsi:295 */
			interrupt-names = "global";   /* in zephyr/dts/arm/gd/gd32e10x/gd32e10x.dtsi:296 */
			clocks = < &cctl 0x702 >;     /* in zephyr/dts/arm/gd/gd32e10x/gd32e10x.dtsi:297 */
			resets = < &rctl 0x402 >;     /* in zephyr/dts/arm/gd/gd32e10x/gd32e10x.dtsi:298 */
			channels = < 0x4 >;           /* in zephyr/dts/arm/gd/gd32e10x/gd32e10x.dtsi:299 */
			status = "disabled";          /* in zephyr/dts/arm/gd/gd32e10x/gd32e10x.dtsi:300 */

			/* node '/soc/timer@40000800/pwm' defined in zephyr/dts/arm/gd/gd32e10x/gd32e10x.dtsi:302 */
			pwm {
				compatible = "gd,gd32-pwm"; /* in zephyr/dts/arm/gd/gd32e10x/gd32e10x.dtsi:303 */
				status = "disabled";        /* in zephyr/dts/arm/gd/gd32e10x/gd32e10x.dtsi:304 */
				#pwm-cells = < 0x3 >;       /* in zephyr/dts/arm/gd/gd32e10x/gd32e10x.dtsi:305 */
			};
		};

		/* node '/soc/timer@40000c00' defined in zephyr/dts/arm/gd/gd32e10x/gd32e10x.dtsi:309 */
		timer4: timer@40000c00 {
			compatible = "gd,gd32-timer"; /* in zephyr/dts/arm/gd/gd32e10x/gd32e10x.dtsi:310 */
			reg = < 0x40000c00 0x400 >;   /* in zephyr/dts/arm/gd/gd32e10x/gd32e10x.dtsi:311 */
			interrupts = < 0x32 0x0 >;    /* in zephyr/dts/arm/gd/gd32e10x/gd32e10x.dtsi:312 */
			interrupt-names = "global";   /* in zephyr/dts/arm/gd/gd32e10x/gd32e10x.dtsi:313 */
			clocks = < &cctl 0x703 >;     /* in zephyr/dts/arm/gd/gd32e10x/gd32e10x.dtsi:314 */
			resets = < &rctl 0x403 >;     /* in zephyr/dts/arm/gd/gd32e10x/gd32e10x.dtsi:315 */
			channels = < 0x4 >;           /* in zephyr/dts/arm/gd/gd32e10x/gd32e10x.dtsi:316 */
			status = "disabled";          /* in zephyr/dts/arm/gd/gd32e10x/gd32e10x.dtsi:317 */

			/* node '/soc/timer@40000c00/pwm' defined in zephyr/dts/arm/gd/gd32e10x/gd32e10x.dtsi:319 */
			pwm {
				compatible = "gd,gd32-pwm"; /* in zephyr/dts/arm/gd/gd32e10x/gd32e10x.dtsi:320 */
				status = "disabled";        /* in zephyr/dts/arm/gd/gd32e10x/gd32e10x.dtsi:321 */
				#pwm-cells = < 0x3 >;       /* in zephyr/dts/arm/gd/gd32e10x/gd32e10x.dtsi:322 */
			};
		};

		/* node '/soc/timer@40001000' defined in zephyr/dts/arm/gd/gd32e10x/gd32e10x.dtsi:326 */
		timer5: timer@40001000 {
			compatible = "gd,gd32-timer"; /* in zephyr/dts/arm/gd/gd32e10x/gd32e10x.dtsi:327 */
			reg = < 0x40001000 0x400 >;   /* in zephyr/dts/arm/gd/gd32e10x/gd32e10x.dtsi:328 */
			interrupts = < 0x36 0x0 >;    /* in zephyr/dts/arm/gd/gd32e10x/gd32e10x.dtsi:329 */
			interrupt-names = "global";   /* in zephyr/dts/arm/gd/gd32e10x/gd32e10x.dtsi:330 */
			clocks = < &cctl 0x704 >;     /* in zephyr/dts/arm/gd/gd32e10x/gd32e10x.dtsi:331 */
			resets = < &rctl 0x404 >;     /* in zephyr/dts/arm/gd/gd32e10x/gd32e10x.dtsi:332 */
			channels = < 0x0 >;           /* in zephyr/dts/arm/gd/gd32e10x/gd32e10x.dtsi:333 */
			status = "disabled";          /* in zephyr/dts/arm/gd/gd32e10x/gd32e10x.dtsi:334 */
		};

		/* node '/soc/timer@40001400' defined in zephyr/dts/arm/gd/gd32e10x/gd32e10x.dtsi:337 */
		timer6: timer@40001400 {
			compatible = "gd,gd32-timer"; /* in zephyr/dts/arm/gd/gd32e10x/gd32e10x.dtsi:338 */
			reg = < 0x40001400 0x400 >;   /* in zephyr/dts/arm/gd/gd32e10x/gd32e10x.dtsi:339 */
			interrupts = < 0x37 0x0 >;    /* in zephyr/dts/arm/gd/gd32e10x/gd32e10x.dtsi:340 */
			interrupt-names = "global";   /* in zephyr/dts/arm/gd/gd32e10x/gd32e10x.dtsi:341 */
			clocks = < &cctl 0x705 >;     /* in zephyr/dts/arm/gd/gd32e10x/gd32e10x.dtsi:342 */
			resets = < &rctl 0x405 >;     /* in zephyr/dts/arm/gd/gd32e10x/gd32e10x.dtsi:343 */
			channels = < 0x0 >;           /* in zephyr/dts/arm/gd/gd32e10x/gd32e10x.dtsi:344 */
			status = "disabled";          /* in zephyr/dts/arm/gd/gd32e10x/gd32e10x.dtsi:345 */
		};

		/* node '/soc/timer@40013400' defined in zephyr/dts/arm/gd/gd32e10x/gd32e10x.dtsi:348 */
		timer7: timer@40013400 {
			compatible = "gd,gd32-timer"; /* in zephyr/dts/arm/gd/gd32e10x/gd32e10x.dtsi:349 */
			reg = < 0x40013400 0x400 >;   /* in zephyr/dts/arm/gd/gd32e10x/gd32e10x.dtsi:350 */
			interrupts = < 0x2b 0x0 >,
			             < 0x2c 0x0 >,
			             < 0x2d 0x0 >,
			             < 0x2e 0x0 >;    /* in zephyr/dts/arm/gd/gd32e10x/gd32e10x.dtsi:351 */
			interrupt-names = "brk",
			                  "up",
			                  "trgcom",
			                  "cc";       /* in zephyr/dts/arm/gd/gd32e10x/gd32e10x.dtsi:352 */
			clocks = < &cctl 0x60d >;     /* in zephyr/dts/arm/gd/gd32e10x/gd32e10x.dtsi:353 */
			resets = < &rctl 0x30d >;     /* in zephyr/dts/arm/gd/gd32e10x/gd32e10x.dtsi:354 */
			is-advanced;                  /* in zephyr/dts/arm/gd/gd32e10x/gd32e10x.dtsi:355 */
			channels = < 0x4 >;           /* in zephyr/dts/arm/gd/gd32e10x/gd32e10x.dtsi:356 */
			status = "disabled";          /* in zephyr/dts/arm/gd/gd32e10x/gd32e10x.dtsi:357 */

			/* node '/soc/timer@40013400/pwm' defined in zephyr/dts/arm/gd/gd32e10x/gd32e10x.dtsi:359 */
			pwm {
				compatible = "gd,gd32-pwm"; /* in zephyr/dts/arm/gd/gd32e10x/gd32e10x.dtsi:360 */
				status = "disabled";        /* in zephyr/dts/arm/gd/gd32e10x/gd32e10x.dtsi:361 */
				#pwm-cells = < 0x3 >;       /* in zephyr/dts/arm/gd/gd32e10x/gd32e10x.dtsi:362 */
			};
		};

		/* node '/soc/timer@40014c00' defined in zephyr/dts/arm/gd/gd32e10x/gd32e10x.dtsi:366 */
		timer8: timer@40014c00 {
			compatible = "gd,gd32-timer"; /* in zephyr/dts/arm/gd/gd32e10x/gd32e10x.dtsi:367 */
			reg = < 0x40014c00 0x400 >;   /* in zephyr/dts/arm/gd/gd32e10x/gd32e10x.dtsi:368 */
			interrupts = < 0x18 0x0 >;    /* in zephyr/dts/arm/gd/gd32e10x/gd32e10x.dtsi:369 */
			interrupt-names = "global";   /* in zephyr/dts/arm/gd/gd32e10x/gd32e10x.dtsi:370 */
			clocks = < &cctl 0x613 >;     /* in zephyr/dts/arm/gd/gd32e10x/gd32e10x.dtsi:371 */
			resets = < &rctl 0x313 >;     /* in zephyr/dts/arm/gd/gd32e10x/gd32e10x.dtsi:372 */
			channels = < 0x2 >;           /* in zephyr/dts/arm/gd/gd32e10x/gd32e10x.dtsi:373 */
			status = "disabled";          /* in zephyr/dts/arm/gd/gd32e10x/gd32e10x.dtsi:374 */

			/* node '/soc/timer@40014c00/pwm' defined in zephyr/dts/arm/gd/gd32e10x/gd32e10x.dtsi:376 */
			pwm {
				compatible = "gd,gd32-pwm"; /* in zephyr/dts/arm/gd/gd32e10x/gd32e10x.dtsi:377 */
				status = "disabled";        /* in zephyr/dts/arm/gd/gd32e10x/gd32e10x.dtsi:378 */
				#pwm-cells = < 0x3 >;       /* in zephyr/dts/arm/gd/gd32e10x/gd32e10x.dtsi:379 */
			};
		};

		/* node '/soc/timer@40015000' defined in zephyr/dts/arm/gd/gd32e10x/gd32e10x.dtsi:383 */
		timer9: timer@40015000 {
			compatible = "gd,gd32-timer"; /* in zephyr/dts/arm/gd/gd32e10x/gd32e10x.dtsi:384 */
			reg = < 0x40015000 0x400 >;   /* in zephyr/dts/arm/gd/gd32e10x/gd32e10x.dtsi:385 */
			interrupts = < 0x19 0x0 >;    /* in zephyr/dts/arm/gd/gd32e10x/gd32e10x.dtsi:386 */
			interrupt-names = "global";   /* in zephyr/dts/arm/gd/gd32e10x/gd32e10x.dtsi:387 */
			clocks = < &cctl 0x614 >;     /* in zephyr/dts/arm/gd/gd32e10x/gd32e10x.dtsi:388 */
			resets = < &rctl 0x314 >;     /* in zephyr/dts/arm/gd/gd32e10x/gd32e10x.dtsi:389 */
			channels = < 0x1 >;           /* in zephyr/dts/arm/gd/gd32e10x/gd32e10x.dtsi:390 */
			status = "disabled";          /* in zephyr/dts/arm/gd/gd32e10x/gd32e10x.dtsi:391 */

			/* node '/soc/timer@40015000/pwm' defined in zephyr/dts/arm/gd/gd32e10x/gd32e10x.dtsi:393 */
			pwm {
				compatible = "gd,gd32-pwm"; /* in zephyr/dts/arm/gd/gd32e10x/gd32e10x.dtsi:394 */
				status = "disabled";        /* in zephyr/dts/arm/gd/gd32e10x/gd32e10x.dtsi:395 */
				#pwm-cells = < 0x3 >;       /* in zephyr/dts/arm/gd/gd32e10x/gd32e10x.dtsi:396 */
			};
		};

		/* node '/soc/timer@40015400' defined in zephyr/dts/arm/gd/gd32e10x/gd32e10x.dtsi:400 */
		timer10: timer@40015400 {
			compatible = "gd,gd32-timer"; /* in zephyr/dts/arm/gd/gd32e10x/gd32e10x.dtsi:401 */
			reg = < 0x40015400 0x400 >;   /* in zephyr/dts/arm/gd/gd32e10x/gd32e10x.dtsi:402 */
			interrupts = < 0x1a 0x0 >;    /* in zephyr/dts/arm/gd/gd32e10x/gd32e10x.dtsi:403 */
			interrupt-names = "global";   /* in zephyr/dts/arm/gd/gd32e10x/gd32e10x.dtsi:404 */
			clocks = < &cctl 0x615 >;     /* in zephyr/dts/arm/gd/gd32e10x/gd32e10x.dtsi:405 */
			resets = < &rctl 0x315 >;     /* in zephyr/dts/arm/gd/gd32e10x/gd32e10x.dtsi:406 */
			channels = < 0x1 >;           /* in zephyr/dts/arm/gd/gd32e10x/gd32e10x.dtsi:407 */
			status = "disabled";          /* in zephyr/dts/arm/gd/gd32e10x/gd32e10x.dtsi:408 */

			/* node '/soc/timer@40015400/pwm' defined in zephyr/dts/arm/gd/gd32e10x/gd32e10x.dtsi:410 */
			pwm {
				compatible = "gd,gd32-pwm"; /* in zephyr/dts/arm/gd/gd32e10x/gd32e10x.dtsi:411 */
				status = "disabled";        /* in zephyr/dts/arm/gd/gd32e10x/gd32e10x.dtsi:412 */
				#pwm-cells = < 0x3 >;       /* in zephyr/dts/arm/gd/gd32e10x/gd32e10x.dtsi:413 */
			};
		};

		/* node '/soc/timer@40001800' defined in zephyr/dts/arm/gd/gd32e10x/gd32e10x.dtsi:417 */
		timer11: timer@40001800 {
			compatible = "gd,gd32-timer"; /* in zephyr/dts/arm/gd/gd32e10x/gd32e10x.dtsi:418 */
			reg = < 0x40001800 0x400 >;   /* in zephyr/dts/arm/gd/gd32e10x/gd32e10x.dtsi:419 */
			interrupts = < 0x2b 0x0 >;    /* in zephyr/dts/arm/gd/gd32e10x/gd32e10x.dtsi:420 */
			interrupt-names = "global";   /* in zephyr/dts/arm/gd/gd32e10x/gd32e10x.dtsi:421 */
			clocks = < &cctl 0x706 >;     /* in zephyr/dts/arm/gd/gd32e10x/gd32e10x.dtsi:422 */
			resets = < &rctl 0x406 >;     /* in zephyr/dts/arm/gd/gd32e10x/gd32e10x.dtsi:423 */
			channels = < 0x2 >;           /* in zephyr/dts/arm/gd/gd32e10x/gd32e10x.dtsi:424 */
			status = "disabled";          /* in zephyr/dts/arm/gd/gd32e10x/gd32e10x.dtsi:425 */

			/* node '/soc/timer@40001800/pwm' defined in zephyr/dts/arm/gd/gd32e10x/gd32e10x.dtsi:427 */
			pwm {
				compatible = "gd,gd32-pwm"; /* in zephyr/dts/arm/gd/gd32e10x/gd32e10x.dtsi:428 */
				status = "disabled";        /* in zephyr/dts/arm/gd/gd32e10x/gd32e10x.dtsi:429 */
				#pwm-cells = < 0x3 >;       /* in zephyr/dts/arm/gd/gd32e10x/gd32e10x.dtsi:430 */
			};
		};

		/* node '/soc/timer@40001c00' defined in zephyr/dts/arm/gd/gd32e10x/gd32e10x.dtsi:434 */
		timer12: timer@40001c00 {
			compatible = "gd,gd32-timer"; /* in zephyr/dts/arm/gd/gd32e10x/gd32e10x.dtsi:435 */
			reg = < 0x40001c00 0x400 >;   /* in zephyr/dts/arm/gd/gd32e10x/gd32e10x.dtsi:436 */
			interrupts = < 0x2c 0x0 >;    /* in zephyr/dts/arm/gd/gd32e10x/gd32e10x.dtsi:437 */
			interrupt-names = "global";   /* in zephyr/dts/arm/gd/gd32e10x/gd32e10x.dtsi:438 */
			clocks = < &cctl 0x707 >;     /* in zephyr/dts/arm/gd/gd32e10x/gd32e10x.dtsi:439 */
			resets = < &rctl 0x407 >;     /* in zephyr/dts/arm/gd/gd32e10x/gd32e10x.dtsi:440 */
			channels = < 0x1 >;           /* in zephyr/dts/arm/gd/gd32e10x/gd32e10x.dtsi:441 */
			status = "disabled";          /* in zephyr/dts/arm/gd/gd32e10x/gd32e10x.dtsi:442 */

			/* node '/soc/timer@40001c00/pwm' defined in zephyr/dts/arm/gd/gd32e10x/gd32e10x.dtsi:444 */
			pwm {
				compatible = "gd,gd32-pwm"; /* in zephyr/dts/arm/gd/gd32e10x/gd32e10x.dtsi:445 */
				status = "disabled";        /* in zephyr/dts/arm/gd/gd32e10x/gd32e10x.dtsi:446 */
				#pwm-cells = < 0x3 >;       /* in zephyr/dts/arm/gd/gd32e10x/gd32e10x.dtsi:447 */
			};
		};

		/* node '/soc/timer@40002000' defined in zephyr/dts/arm/gd/gd32e10x/gd32e10x.dtsi:451 */
		timer13: timer@40002000 {
			compatible = "gd,gd32-timer"; /* in zephyr/dts/arm/gd/gd32e10x/gd32e10x.dtsi:452 */
			reg = < 0x40002000 0x400 >;   /* in zephyr/dts/arm/gd/gd32e10x/gd32e10x.dtsi:453 */
			interrupts = < 0x2d 0x0 >;    /* in zephyr/dts/arm/gd/gd32e10x/gd32e10x.dtsi:454 */
			interrupt-names = "global";   /* in zephyr/dts/arm/gd/gd32e10x/gd32e10x.dtsi:455 */
			clocks = < &cctl 0x708 >;     /* in zephyr/dts/arm/gd/gd32e10x/gd32e10x.dtsi:456 */
			resets = < &rctl 0x408 >;     /* in zephyr/dts/arm/gd/gd32e10x/gd32e10x.dtsi:457 */
			channels = < 0x1 >;           /* in zephyr/dts/arm/gd/gd32e10x/gd32e10x.dtsi:458 */
			status = "disabled";          /* in zephyr/dts/arm/gd/gd32e10x/gd32e10x.dtsi:459 */

			/* node '/soc/timer@40002000/pwm' defined in zephyr/dts/arm/gd/gd32e10x/gd32e10x.dtsi:461 */
			pwm {
				compatible = "gd,gd32-pwm"; /* in zephyr/dts/arm/gd/gd32e10x/gd32e10x.dtsi:462 */
				status = "disabled";        /* in zephyr/dts/arm/gd/gd32e10x/gd32e10x.dtsi:463 */
				#pwm-cells = < 0x3 >;       /* in zephyr/dts/arm/gd/gd32e10x/gd32e10x.dtsi:464 */
			};
		};

		/* node '/soc/dma@40020000' defined in zephyr/dts/arm/gd/gd32e10x/gd32e10x.dtsi:468 */
		dma0: dma@40020000 {
			compatible = "gd,gd32-dma"; /* in zephyr/dts/arm/gd/gd32e10x/gd32e10x.dtsi:469 */
			reg = < 0x40020000 0x400 >; /* in zephyr/dts/arm/gd/gd32e10x/gd32e10x.dtsi:470 */
			interrupts = < 0xb 0x0 >,
			             < 0xc 0x0 >,
			             < 0xd 0x0 >,
			             < 0xe 0x0 >,
			             < 0xf 0x0 >,
			             < 0x10 0x0 >,
			             < 0x11 0x0 >;  /* in zephyr/dts/arm/gd/gd32e10x/gd32e10x.dtsi:471 */
			clocks = < &cctl 0x500 >;   /* in zephyr/dts/arm/gd/gd32e10x/gd32e10x.dtsi:473 */
			dma-channels = < 0x7 >;     /* in zephyr/dts/arm/gd/gd32e10x/gd32e10x.dtsi:474 */
			#dma-cells = < 0x2 >;       /* in zephyr/dts/arm/gd/gd32e10x/gd32e10x.dtsi:475 */
			status = "disabled";        /* in zephyr/dts/arm/gd/gd32e10x/gd32e10x.dtsi:476 */
		};

		/* node '/soc/dma@40020400' defined in zephyr/dts/arm/gd/gd32e10x/gd32e10x.dtsi:479 */
		dma1: dma@40020400 {
			compatible = "gd,gd32-dma"; /* in zephyr/dts/arm/gd/gd32e10x/gd32e10x.dtsi:480 */
			reg = < 0x40020400 0x400 >; /* in zephyr/dts/arm/gd/gd32e10x/gd32e10x.dtsi:481 */
			interrupts = < 0x38 0x0 >,
			             < 0x39 0x0 >,
			             < 0x3a 0x0 >,
			             < 0x3b 0x0 >,
			             < 0x3c 0x0 >;  /* in zephyr/dts/arm/gd/gd32e10x/gd32e10x.dtsi:482 */
			clocks = < &cctl 0x501 >;   /* in zephyr/dts/arm/gd/gd32e10x/gd32e10x.dtsi:484 */
			dma-channels = < 0x5 >;     /* in zephyr/dts/arm/gd/gd32e10x/gd32e10x.dtsi:485 */
			#dma-cells = < 0x2 >;       /* in zephyr/dts/arm/gd/gd32e10x/gd32e10x.dtsi:486 */
			status = "disabled";        /* in zephyr/dts/arm/gd/gd32e10x/gd32e10x.dtsi:487 */
		};
	};

	/* node '/cpus' defined in zephyr/dts/arm/gd/gd32e10x/gd32e10x.dtsi:16 */
	cpus {
		#address-cells = < 0x1 >; /* in zephyr/dts/arm/gd/gd32e10x/gd32e10x.dtsi:17 */
		#size-cells = < 0x0 >;    /* in zephyr/dts/arm/gd/gd32e10x/gd32e10x.dtsi:18 */

		/* node '/cpus/cpu@0' defined in zephyr/dts/arm/gd/gd32e10x/gd32e10x.dtsi:20 */
		cpu0: cpu@0 {
			clock-frequency = < 0x7270e00 >; /* in zephyr/dts/arm/gd/gd32e10x/gd32e10x.dtsi:21 */
			compatible = "arm,cortex-m4f";   /* in zephyr/dts/arm/gd/gd32e10x/gd32e10x.dtsi:22 */
			reg = < 0x0 >;                   /* in zephyr/dts/arm/gd/gd32e10x/gd32e10x.dtsi:23 */
			#address-cells = < 0x1 >;        /* in zephyr/dts/arm/gd/gd32e10x/gd32e10x.dtsi:24 */
			#size-cells = < 0x1 >;           /* in zephyr/dts/arm/gd/gd32e10x/gd32e10x.dtsi:25 */
		};
	};

	/* node '/leds' defined in zephyr/boards/gd/gd32e103v_eval/gd32e103v_eval.dts:24 */
	leds {
		compatible = "gpio-leds"; /* in zephyr/boards/gd/gd32e103v_eval/gd32e103v_eval.dts:25 */

		/* node '/leds/led2' defined in zephyr/boards/gd/gd32e103v_eval/gd32e103v_eval.dts:27 */
		led2: led2 {
			gpios = < &gpioc 0x0 0x0 >; /* in zephyr/boards/gd/gd32e103v_eval/gd32e103v_eval.dts:28 */
			label = "LED2";             /* in zephyr/boards/gd/gd32e103v_eval/gd32e103v_eval.dts:29 */
		};

		/* node '/leds/led3' defined in zephyr/boards/gd/gd32e103v_eval/gd32e103v_eval.dts:32 */
		led3: led3 {
			gpios = < &gpioc 0x2 0x0 >; /* in zephyr/boards/gd/gd32e103v_eval/gd32e103v_eval.dts:33 */
			label = "LED3";             /* in zephyr/boards/gd/gd32e103v_eval/gd32e103v_eval.dts:34 */
		};

		/* node '/leds/led4' defined in zephyr/boards/gd/gd32e103v_eval/gd32e103v_eval.dts:37 */
		led4: led4 {
			gpios = < &gpioe 0x0 0x0 >; /* in zephyr/boards/gd/gd32e103v_eval/gd32e103v_eval.dts:38 */
			label = "LED4";             /* in zephyr/boards/gd/gd32e103v_eval/gd32e103v_eval.dts:39 */
		};

		/* node '/leds/led5' defined in zephyr/boards/gd/gd32e103v_eval/gd32e103v_eval.dts:42 */
		led5: led5 {
			gpios = < &gpioe 0x1 0x0 >; /* in zephyr/boards/gd/gd32e103v_eval/gd32e103v_eval.dts:43 */
			label = "LED5";             /* in zephyr/boards/gd/gd32e103v_eval/gd32e103v_eval.dts:44 */
		};
	};

	/* node '/gpio_keys' defined in zephyr/boards/gd/gd32e103v_eval/gd32e103v_eval.dts:48 */
	gpio_keys {
		compatible = "gpio-keys"; /* in zephyr/boards/gd/gd32e103v_eval/gd32e103v_eval.dts:49 */

		/* node '/gpio_keys/wakeup_key' defined in zephyr/boards/gd/gd32e103v_eval/gd32e103v_eval.dts:51 */
		wakeup_key: wakeup_key {
			label = "WAKEUP_KEY";       /* in zephyr/boards/gd/gd32e103v_eval/gd32e103v_eval.dts:52 */
			gpios = < &gpioa 0x0 0x1 >; /* in zephyr/boards/gd/gd32e103v_eval/gd32e103v_eval.dts:53 */
			zephyr,code = < 0x8f >;     /* in zephyr/boards/gd/gd32e103v_eval/gd32e103v_eval.dts:54 */
		};

		/* node '/gpio_keys/tamper_key' defined in zephyr/boards/gd/gd32e103v_eval/gd32e103v_eval.dts:57 */
		tamper_key: tamper_key {
			label = "TAMPER_KEY";       /* in zephyr/boards/gd/gd32e103v_eval/gd32e103v_eval.dts:58 */
			gpios = < &gpioc 0xd 0x1 >; /* in zephyr/boards/gd/gd32e103v_eval/gd32e103v_eval.dts:59 */
			zephyr,code = < 0xb >;      /* in zephyr/boards/gd/gd32e103v_eval/gd32e103v_eval.dts:60 */
		};

		/* node '/gpio_keys/user_key' defined in zephyr/boards/gd/gd32e103v_eval/gd32e103v_eval.dts:63 */
		user_key: user_key {
			label = "USER_KEY1";        /* in zephyr/boards/gd/gd32e103v_eval/gd32e103v_eval.dts:64 */
			gpios = < &gpiob 0xe 0x1 >; /* in zephyr/boards/gd/gd32e103v_eval/gd32e103v_eval.dts:65 */
			zephyr,code = < 0x2 >;      /* in zephyr/boards/gd/gd32e103v_eval/gd32e103v_eval.dts:66 */
		};
	};

	/* node '/pwmleds' defined in zephyr/boards/gd/gd32e103v_eval/gd32e103v_eval.dts:70 */
	pwmleds {
		compatible = "pwm-leds"; /* in zephyr/boards/gd/gd32e103v_eval/gd32e103v_eval.dts:71 */

		/* node '/pwmleds/pwm_led' defined in zephyr/boards/gd/gd32e103v_eval/gd32e103v_eval.dts:74 */
		pwm_led: pwm_led {
			pwms = < &pwm0 0x0 0x1312d00 0x0 >; /* in zephyr/boards/gd/gd32e103v_eval/gd32e103v_eval.dts:75 */
		};
	};
};
